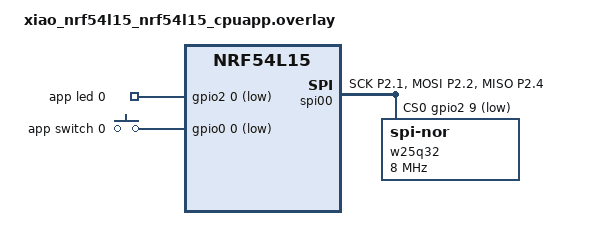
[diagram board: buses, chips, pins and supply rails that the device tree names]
/ {
    gpiocustom {
        compatible = "gpio-keys";
        appled0: appled_0 {
            gpios = <&gpio2 0 GPIO_ACTIVE_LOW>;
            label = "app led 0";
        };

        appsw_0: appsw_0 {
            gpios = <&gpio0 0 (GPIO_PULL_UP | GPIO_ACTIVE_LOW)>;
            label = "app switch 0";
        };
    };

    aliases {
        appled0 = &appled0;
        appsw0 = &appsw_0;
		appflash = &w25q32;
    };
};

&spi00{
	compatible = "nordic,nrf-spim";
	status = "okay";
	pinctrl-0 = <&spi00_default>;
	pinctrl-1 = <&spi00_sleep>;
	pinctrl-names = "default", "sleep";
	cs-gpios = <&gpio2 9 GPIO_ACTIVE_LOW>;

	w25q32: w25q32@0 {
        compatible = "jedec,spi-nor";
        reg = <0>;
        spi-max-frequency = <8000000>;
    };
};

&pinctrl {

	spi00_default: spi00_default {
		group1 {
			psels = <NRF_PSEL(SPIM_SCK, 2, 1)>,
				<NRF_PSEL(SPIM_MOSI, 2, 2)>,
				<NRF_PSEL(SPIM_MISO, 2, 4)>;
		};
	};

	spi00_sleep: spi00_sleep {
		group1 {
			psels = <NRF_PSEL(SPIM_SCK, 2, 1)>,
				<NRF_PSEL(SPIM_MOSI, 2, 2)>,
				<NRF_PSEL(SPIM_MISO, 2, 4)>;
			low-power-enable;
		};
	};
};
